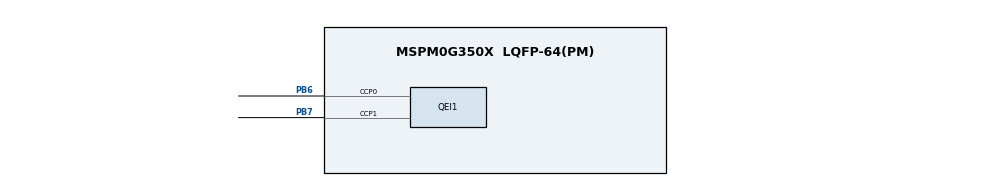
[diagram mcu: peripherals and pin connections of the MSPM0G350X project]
/**
 * @cliArgs --device "MSPM0G350X" --part "Default" --package "LQFP-64(PM)" --product "mspm0_sdk@2.06.00.05"
 * @versions {"tool":"1.21.0+3721"}
 */

/**
 * Import the modules used in this configuration.
 */
const ADC12  = scripting.addModule("/ti/driverlib/ADC12", {}, false);
const ADC121 = ADC12.addInstance();
const DAC12  = scripting.addModule("/ti/driverlib/DAC12");
const GPIO   = scripting.addModule("/ti/driverlib/GPIO", {}, false);
const GPIO1  = GPIO.addInstance();
const GPIO2  = GPIO.addInstance();
const GPIO3  = GPIO.addInstance();
const GPIO4  = GPIO.addInstance();
const QEI    = scripting.addModule("/ti/driverlib/QEI", {}, false);
const QEI1   = QEI.addInstance();
const SYSCTL = scripting.addModule("/ti/driverlib/SYSCTL");
const TIMER  = scripting.addModule("/ti/driverlib/TIMER", {}, false);
const TIMER1 = TIMER.addInstance();
const TIMER2 = TIMER.addInstance();

/**
 * Write custom configuration values to the imported modules.
 */
const divider4       = system.clockTree["PLL_CLK0_DIV"];
divider4.divideValue = 10;

const divider9       = system.clockTree["UDIV"];
divider9.divideValue = 2;

const gate8  = system.clockTree["MFPCLKGATE"];
gate8.enable = true;

const mux4       = system.clockTree["EXHFMUX"];
mux4.inputSelect = "EXHFMUX_XTAL";

const mux8       = system.clockTree["HSCLKMUX"];
mux8.inputSelect = "HSCLKMUX_SYSPLL0";

const mux12       = system.clockTree["SYSPLLMUX"];
mux12.inputSelect = "zSYSPLLMUX_HFCLK";

const pinFunction4     = system.clockTree["HFXT"];
pinFunction4.enable    = true;
pinFunction4.inputFreq = 40;

ADC121.$name               = "ADC12_0";
ADC121.adcMem0chansel      = "DL_ADC12_INPUT_CHAN_2";
ADC121.peripheral.$assign  = "ADC0";
ADC121.adcPin2Config.$name = "ti_driverlib_gpio_GPIOPinGeneric3";

const Board = scripting.addModule("/ti/driverlib/Board", {}, false);

DAC12.dacFIFOEn                = true;
DAC12.dacFIFOTrigger           = "HWTRIG0";
DAC12.sub0ChanID               = 1;
DAC12.dacOutputPinEn           = true;
DAC12.dacAmplifier             = "ON";
DAC12.dacConfigureDMA          = true;
DAC12.dacFIFOThresh            = "TWO_QTRS_EMPTY";
DAC12.dacSampleTimerRate       = "1M";
DAC12.dacEnabledInterrupts     = ["DMA_DONE"];
DAC12.OutPinConfig.$name       = "ti_driverlib_gpio_GPIOPinGeneric0";
DAC12.DMA_CHANNEL.$name        = "DMA_CH0";
DAC12.DMA_CHANNEL.srcLength    = "HALF_WORD";
DAC12.DMA_CHANNEL.dstLength    = "HALF_WORD";
DAC12.DMA_CHANNEL.addressMode  = "b2f";
DAC12.DMA_CHANNEL.transferMode = "FULL_CH_REPEAT_SINGLE";

GPIO1.$name                          = "GPIO_OLED_13";
GPIO1.associatedPins.create(2);
GPIO1.associatedPins[0].$name        = "GPIO_SDA";
GPIO1.associatedPins[0].assignedPort = "PORTA";
GPIO1.associatedPins[0].assignedPin  = "28";
GPIO1.associatedPins[1].$name        = "GPIO_SCK";
GPIO1.associatedPins[1].assignedPort = "PORTA";
GPIO1.associatedPins[1].assignedPin  = "31";

GPIO2.$name                                 = "GPIO_EC11";
GPIO2.port                                  = "PORTA";
GPIO2.associatedPins[0].direction           = "INPUT";
GPIO2.associatedPins[0].assignedPin         = "18";
GPIO2.associatedPins[0].interruptEn         = true;
GPIO2.associatedPins[0].$name               = "SW";
GPIO2.associatedPins[0].assignedPortSegment = "Upper";
GPIO2.associatedPins[0].polarity            = "RISE";

GPIO3.$name                          = "GPIO_LED";
GPIO3.associatedPins[0].$name        = "PIN_0";
GPIO3.associatedPins[0].assignedPort = "PORTA";
GPIO3.associatedPins[0].assignedPin  = "0";

GPIO4.$name                          = "GPIO_SET";
GPIO4.associatedPins[0].$name        = "PIN_1";
GPIO4.associatedPins[0].assignedPort = "PORTB";
GPIO4.associatedPins[0].assignedPin  = "22";

QEI1.$name                              = "TIMER_QEI";
QEI1.enableIndexInput                   = true;
QEI1.retentionRestoreCnt                = true;
QEI1.interrupts                         = ["ZERO_EVENT"];
QEI1.clockPrescale                      = 10;
QEI1.peripheral.$assign                 = "TIMG8";
QEI1.peripheral.ccp0Pin.$assign         = "PB6";
QEI1.peripheral.ccp1Pin.$assign         = "PB7";
QEI1.ccp0PinConfig.$name                = "ti_driverlib_gpio_GPIOPinGeneric1";
QEI1.ccp0PinConfig.hideOutputInversion  = scripting.forceWrite(false);
QEI1.ccp0PinConfig.onlyInternalResistor = scripting.forceWrite(false);
QEI1.ccp0PinConfig.passedPeripheralType = scripting.forceWrite("Digital");
QEI1.ccp1PinConfig.$name                = "ti_driverlib_gpio_GPIOPinGeneric2";
QEI1.ccp1PinConfig.hideOutputInversion  = scripting.forceWrite(false);
QEI1.ccp1PinConfig.onlyInternalResistor = scripting.forceWrite(false);
QEI1.ccp1PinConfig.passedPeripheralType = scripting.forceWrite("Digital");
QEI1.idxPinConfig.$name                 = "ti_driverlib_gpio_GPIOPinGeneric4";

SYSCTL.MFPCLKEn              = true;
SYSCTL.enableSleepOnExit     = true;
SYSCTL.forceDefaultClkConfig = true;
SYSCTL.clockTreeEn           = true;

TIMER1.$name                       = "TIMER_0";
TIMER1.timerMode                   = "PERIODIC";
TIMER1.event1PublisherChannel      = 1;
TIMER1.event1ControllerInterruptEn = ["ZERO_EVENT"];
TIMER1.timerPeriod                 = "50us";
TIMER1.peripheral.$assign          = "TIMA0";

TIMER2.$name       = "TIMER_MS";
TIMER2.timerPeriod = "1 ms";
TIMER2.timerMode   = "PERIODIC_UP";
TIMER2.timerClkDiv = 8;

/**
 * Pinmux solution for unlocked pins/peripherals. This ensures that minor changes to the automatic solver in a future
 * version of the tool will not impact the pinmux you originally saw.  These lines can be completely deleted in order to
 * re-solve from scratch.
 */
pinFunction4.peripheral.$suggestSolution           = "SYSCTL";
pinFunction4.peripheral.hfxInPin.$suggestSolution  = "PA5";
pinFunction4.peripheral.hfxOutPin.$suggestSolution = "PA6";
ADC121.peripheral.adcPin2.$suggestSolution         = "PA25";
Board.peripheral.$suggestSolution                  = "DEBUGSS";
Board.peripheral.swclkPin.$suggestSolution         = "PA20";
Board.peripheral.swdioPin.$suggestSolution         = "PA19";
DAC12.peripheral.$suggestSolution                  = "DAC0";
DAC12.peripheral.OutPin.$suggestSolution           = "PA15";
DAC12.DMA_CHANNEL.peripheral.$suggestSolution      = "DMA_CH0";
GPIO1.associatedPins[0].pin.$suggestSolution       = "PA28";
GPIO1.associatedPins[1].pin.$suggestSolution       = "PA31";
GPIO2.associatedPins[0].pin.$suggestSolution       = "PA18";
GPIO3.associatedPins[0].pin.$suggestSolution       = "PA0";
GPIO4.associatedPins[0].pin.$suggestSolution       = "PB22";
QEI1.peripheral.idxPin.$suggestSolution            = "PA1";
TIMER2.peripheral.$suggestSolution                 = "TIMA1";
